# G32R430xx register map
Vendor: Geehy Semiconductor Co., Ltd.; Series: G32R4; File version: 1.0
CPU: CM52 r0p1, little endian, MPU, no FPU, DSP, VTOR, 4 interrupt priority bits
Registers are 32-bit, read-write, reset 0x0 unless marked. A register's access mark holds for its fields unless they carry their own. Offsets are from the block's base; [hi:lo] are bit positions; lines under a group give offsets from that group; {n}, {i} and the like mark numbered series.

## ADC3 — Analog to digital converter(12 bit)
Base 0x40021400
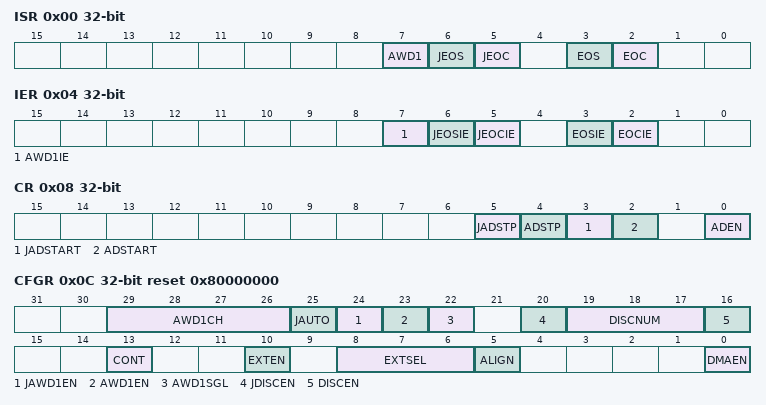
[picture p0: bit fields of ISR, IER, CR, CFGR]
0x00 ISR — ADC interrupt and status register
  [7] AWD1 — ADC analog watchdog 1 flag
  [6] JEOS — ADC group injected end of sequence conversions flag
  [5] JEOC — ADC group injected end of unitary conversion flag
  [3] EOS — ADC group regular end of sequence conversions flag
  [2] EOC — ADC group regular end of unitary conversion flag
0x04 IER — ADC interrupt enable register
  [7] AWD1IE — ADC analog watchdog 1 interrupt
  [6] JEOSIE — ADC group injected end of sequence conversions interrupt
  [5] JEOCIE — ADC group injected end of unitary conversion interrupt
  [3] EOSIE — ADC group regular end of sequence conversions interrupt
  [2] EOCIE — ADC group regular end of unitary conversion interrupt
0x08 CR — ADC control register
  [5] JADSTP — ADC group injected conversion stop
  [4] ADSTP — ADC group regular conversion stop
  [3] JADSTART — ADC group injected conversion start
  [2] ADSTART — ADC group regular conversion start
  [0] ADEN — ADC enable
0x0C CFGR reset 0x80000000 — ADC configuration register 1
  [29:26] AWD1CH — ADC analog watchdog 1 monitored channel selection
  [25] JAUTO — ADC group injected automatic trigger mode
  [24] JAWD1EN — ADC analog watchdog 1 enable on scope ADC group injected
  [23] AWD1EN — ADC analog watchdog 1 enable on scope ADC group regular
  [22] AWD1SGL — ADC analog watchdog 1 monitoring a single channel or all channels
  [20] JDISCEN — ADC group injected sequencer discontinuous mode
  [19:17] DISCNUM — ADC group regular sequencer discontinuous number of ranks
  [16] DISCEN — ADC group regular sequencer discontinuous mode
  [13] CONT — ADC group regular continuous conversion mode
  [10] EXTEN — ADC group regular external trigger polarity
  [8:6] EXTSEL — ADC group regular external trigger source
  [5] ALIGN — ADC data alignment
  [0] DMAEN — ADC DMA transfer enable
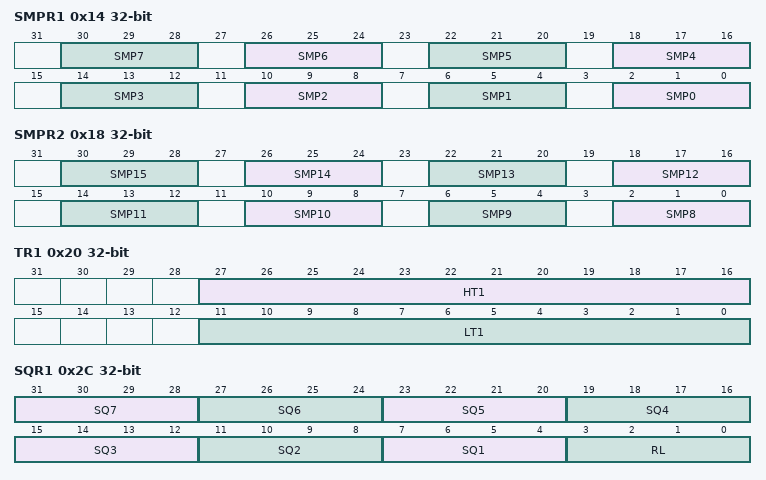
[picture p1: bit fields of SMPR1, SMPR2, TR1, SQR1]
0x14 SMPR1 — ADC sampling time register 1
  [4n+2:4n] SMP{n} (n=0..7) — ADC channel {n} sampling time selection
0x18 SMPR2 — ADC sampling time register 2
  [4n-30:4n-32] SMP{n} (n=8..15) — ADC channel {n} sampling time selection
0x20 TR1 — ADC analog watchdog 1 threshold register
  [27:16] HT1 — ADC analog watchdog 1 threshold high
  [11:0] LT1 — ADC analog watchdog 1 threshold low
0x2C SQR1 — ADC group regular sequencer register 1
  [4n+3:4n] SQ{n} (n=1..7) — ADC group regular sequencer rank {n}
  [3:0] RL — ADC group regular sequencer scan length
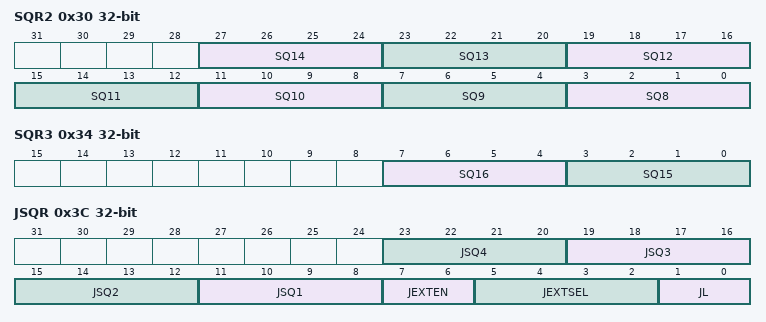
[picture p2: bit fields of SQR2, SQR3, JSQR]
0x30 SQR2 — ADC group regular sequencer register 2
  [4n-29:4n-32] SQ{n} (n=8..14) — ADC group regular sequencer rank {n}
0x34 SQR3 — ADC group regular sequencer register 3
  [7:4] SQ16 — ADC group regular sequencer rank 16
  [3:0] SQ15 — ADC group regular sequencer rank 15
0x38 DR ro — ADC group regular data register
  [15:0] RDATA — ADC group regular conversion data
0x3C JSQR — ADC group injected sequencer register
  [4n+7:4n+4] JSQ{n} (n=1..4) — ADC group injected sequencer rank {n}
  [7:6] JEXTEN — ADC group injected external trigger polarity
  [5:2] JEXTSEL — ADC group injected external trigger source
  [1:0] JL — ADC group injected sequencer scan length
{0x3C+4i} JDR{i} ro (i=1..4) — ADC group injected rank {i} data register
  [15:0] JDATA — ADC group injected sequencer rank {i} conversion data
{0x54+4i} JOFFSET{i} (i=1..4) — ADC offset register {i}
  [11:0] JOFFSET{i}

## SPI1 — Serial peripheral interface
Base 0x40001000
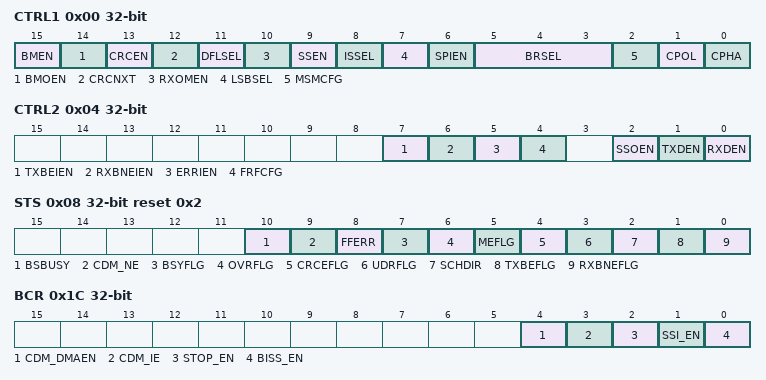
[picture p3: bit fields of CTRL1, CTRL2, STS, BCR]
0x00 CTRL1 — control register 1
  [15] BMEN — Bidirectional data mode enable
  [14] BMOEN — Output enable in bidirectional mode
  [13] CRCEN — Hardware CRC calculation enable
  [12] CRCNXT — CRC transfer next
  [11] DFLSEL — Data frame format
  [10] RXOMEN — Receive only
  [9] SSEN — Software slave management
  [8] ISSEL — Internal slave select
  [7] LSBSEL — Frame format
  [6] SPIEN — SPI enable
  [5:3] BRSEL — Baud rate control
  [2] MSMCFG — Master selection
  [1] CPOL — Clock polarity
  [0] CPHA — Clock phase
0x04 CTRL2 — control register 2
  [7] TXBEIEN — Tx buffer empty interrupt enable
  [6] RXBNEIEN — RX buffer not empty interrupt enable
  [5] ERRIEN — Error interrupt enable
  [4] FRFCFG — Frame Format Configure
  [2] SSOEN — SS output enable
  [1] TXDEN — Tx buffer DMA enable
  [0] RXDEN — Rx buffer DMA enable
0x08 STS access per field reset 0x2 — status register
  [10] BSBUSY ro — Busy in Biss-c/ssi mode
  [9] CDM_NE ro — CDM Non-Empty Status
  [8] FFERR ro — TI frame format error
  [7] BSYFLG ro — Busy flag
  [6] OVRFLG ro — Overrun flag
  [5] MEFLG ro — Mode fault
  [4] CRCEFLG rw — CRC error flag
  [3] UDRFLG ro — Underrun flag
  [2] SCHDIR ro — Channel side
  [1] TXBEFLG ro — Transmit buffer empty
  [0] RXBNEFLG ro — Receive buffer not empty
0x0C DATA
  [15:0] DATA
0x10 CRCPOLY reset 0x7 — CRC polynomial register
  [15:0] CRCPOLY
0x14 RXCRC ro
  [15:0] RXCRC
0x18 TXCRC ro
  [15:0] TXCRC
0x1C BCR — BISS-C Control Register
  [4] CDM_DMAEN, [3] CDM_IE, [2] STOP_EN, [1] SSI_EN, [0] BISS_EN
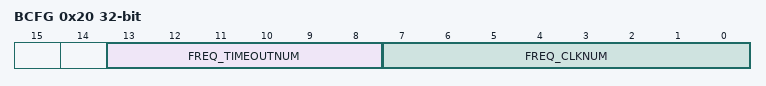
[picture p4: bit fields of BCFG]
0x20 BCFG — BISS-C Configuration Register
  [13:8] FREQ_TIMEOUTNUM, [7:0] FREQ_CLKNUM
0x24 CDMDATA ro
  [0] DATA
